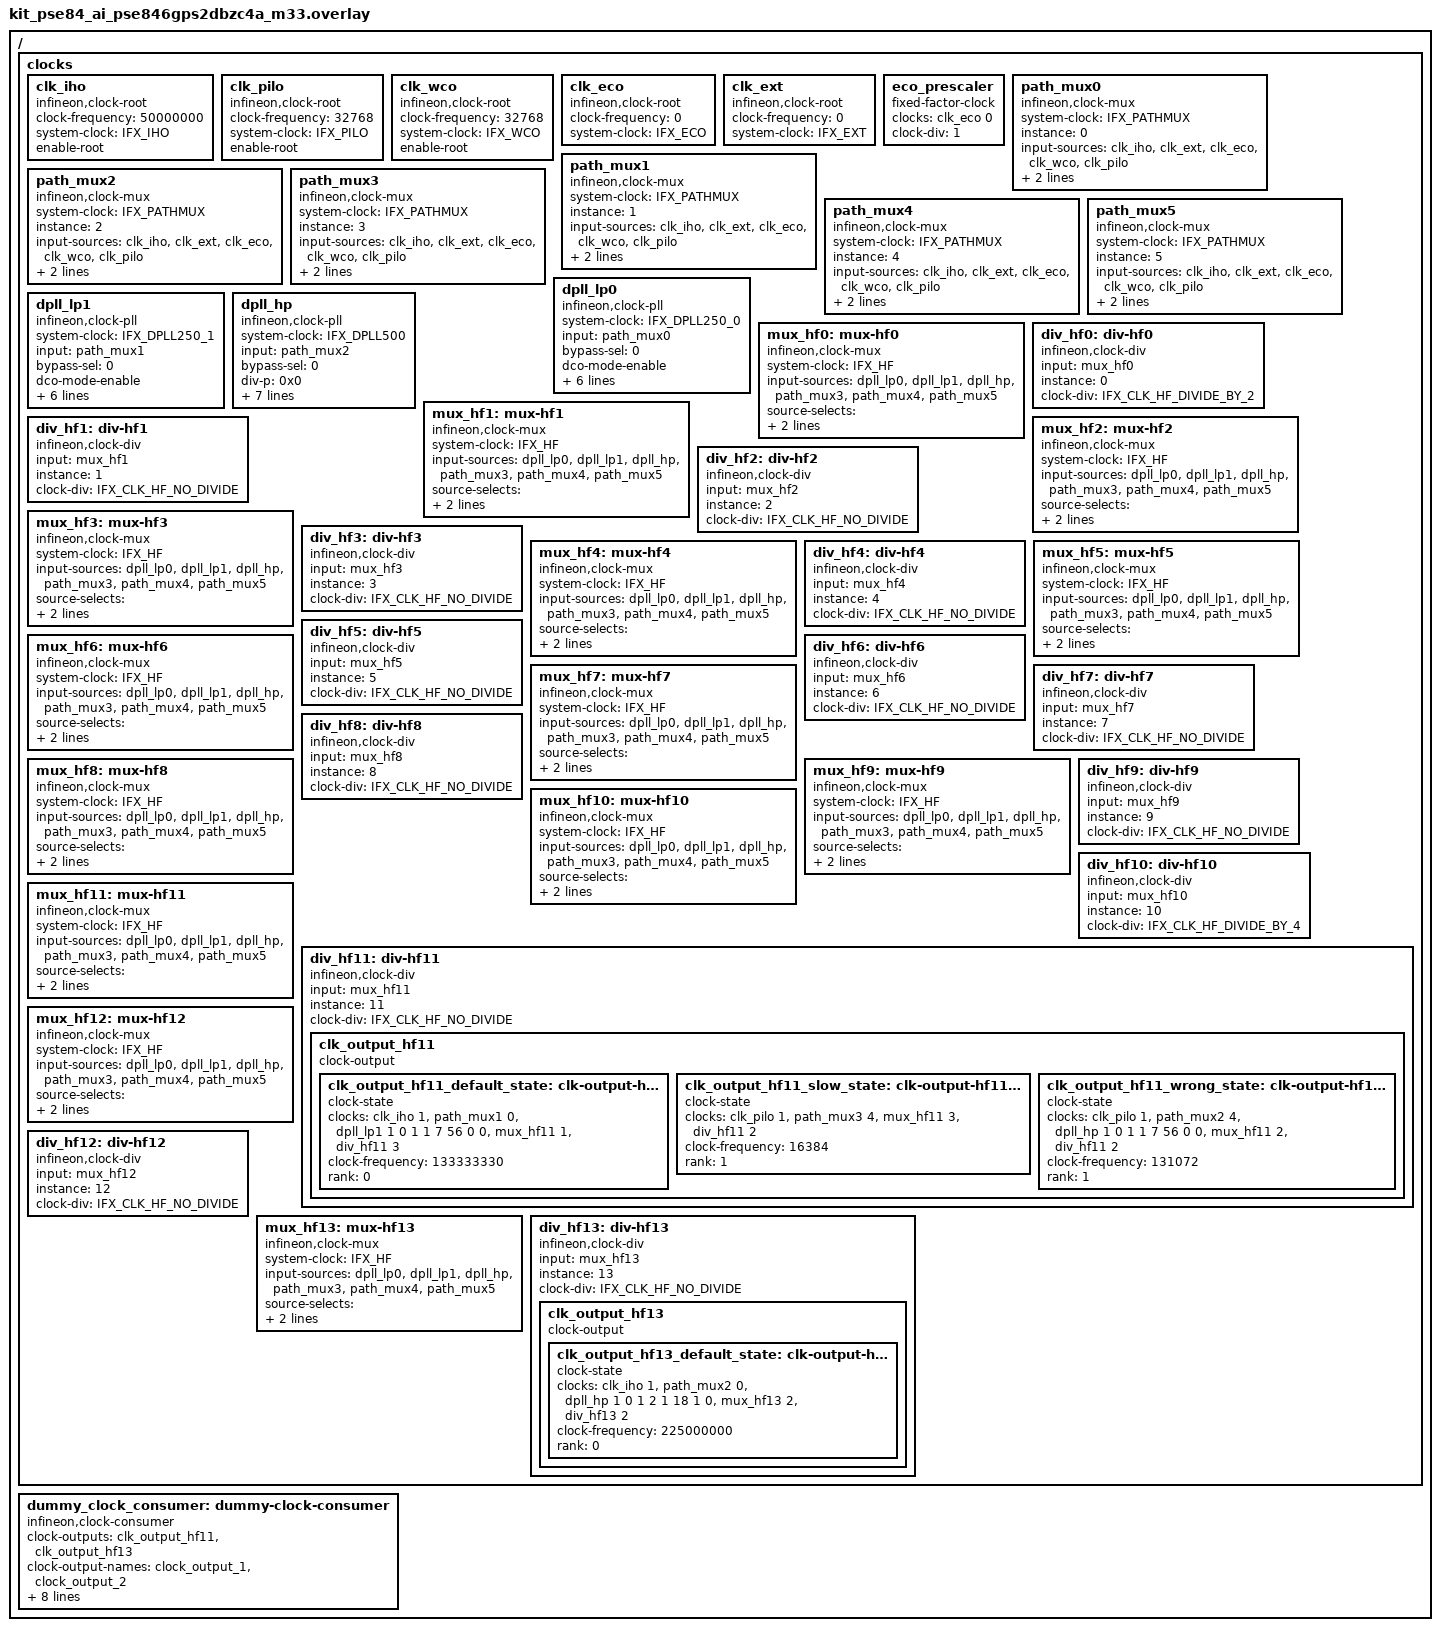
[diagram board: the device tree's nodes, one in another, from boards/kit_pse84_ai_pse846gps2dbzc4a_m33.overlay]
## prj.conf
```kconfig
CONFIG_ZTEST=y
CONFIG_BUILD_OUTPUT_HEX=y
CONFIG_CLOCK_MANAGEMENT=y
```

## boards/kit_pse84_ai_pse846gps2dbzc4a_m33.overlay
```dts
/*
 * SPDX-FileCopyrightText: Copyright (c) 2026 Infineon Technologies AG,
 * or an affiliate of Infineon Technologies AG. All rights reserved.
 *
 * SPDX-License-Identifier: Apache-2.0
 */

/*
 * PSoC Edge E84 clock tree modelled with the clock-management RFC producers.
 *
 * Clock management owns the shared upstream: every source, path multiplexer,
 * DPLL, and clk_hf root is a clock-management producer with real parent phandle
 * links (input / input-sources). The peripheral leaf dividers below stay on the
 * legacy infineon,peri-div clock-control path, owned by the peripheral drivers,
 * so drivers can move to clock management one at a time.
 *
 * Register addresses and bitfield positions on the upstream producers feed the
 * register-direct backend; the PDL backend ignores them. Addresses in the dts
 * file need  register - level driver.
 * Addresses are from the PSOC Control C3 Registers Reference Manual (SRSS chapter).
 *
 * The DPLL programming sequence is retained through the vendor library, so the
 * DPLL producers are used unchanged by both backends.
 */

#include <zephyr/dt-bindings/clock/ifx_clock_source_common.h>
#include <zephyr/dt-bindings/clock/ifx_clock_source_pse8xx.h>

/delete-node/ &clk_iho;
/delete-node/ &clk_pilo;
/delete-node/ &path_mux0;
/delete-node/ &path_mux1;
/delete-node/ &path_mux2;
/delete-node/ &path_mux3;
/delete-node/ &path_mux4;
/delete-node/ &path_mux5;
/delete-node/ &dpll_lp0;
/delete-node/ &dpll_lp1;
/delete-node/ &dpll_hp;
/delete-node/ &clk_hf0;
/delete-node/ &clk_hf1;
/delete-node/ &clk_hf2;
/delete-node/ &clk_hf3;
/delete-node/ &clk_hf4;
/delete-node/ &clk_hf5;
/delete-node/ &clk_hf6;
/delete-node/ &clk_hf7;
/delete-node/ &clk_hf8;
/delete-node/ &clk_hf9;
/delete-node/ &clk_hf10;
/delete-node/ &clk_hf11;
/delete-node/ &clk_hf12;
/delete-node/ &clk_hf13;



/ {
	/* Clock tree 1/3: roots and path muxes (the 3 /clocks blocks merge). */
	clocks {
		/*
		 * Root oscillator sources (TRM 21.3).
		 */

		/*
		 * Default clock source fixed frequency of 50MHz.
		 */
		clk_iho: clk_iho {
			compatible = "infineon,clock-root";
			#clock-cells = <1>;
			clock-frequency = <50000000>;
			system-clock = <IFX_IHO>;
			enable-root;
			status = "okay";
		};

		/*
		 * Precision-Low Power clock. 
		 */

		clk_pilo: clk_pilo {
			compatible = "infineon,clock-root";
			#clock-cells = <1>;
			clock-frequency = <32768>;
			system-clock = <IFX_PILO>;
			enable-root;
			status = "okay";
		};

		clk_wco: clk_wco {
			compatible = "infineon,clock-root";
			#clock-cells = <1>;
			clock-frequency = <32768>;
			system-clock = <IFX_WCO>;
			enable-root;
			status = "okay";
		};

		/*
		 * ECO and EXT_CLK need board components (a crystal or a driven
		 * clock pin)
		 */
		clk_eco: clk_eco {
			compatible = "infineon,clock-root";
			#clock-cells = <1>;
			clock-frequency = <0>;
			system-clock = <IFX_ECO>;
			status = "okay";
		};


		clk_ext: clk_ext {
			compatible = "infineon,clock-root";
			#clock-cells = <1>;
			clock-frequency = <0>;
			system-clock = <IFX_EXT>;
			status = "okay";
		};

		/*
		 * ECO prescaler (TRM 19.3.7); one of the CLK_LF source options.
		 * Disabled with its ECO parent: the generic fixed-factor
		 * producer would otherwise reference a clock object that a
		 * disabled clk_eco never emits.
		 */
		eco_prescaler: eco_prescaler {
			compatible = "fixed-factor-clock";
			#clock-cells = <0>;
			clocks = <&clk_eco 0>;
			clock-div = <1>;
			status = "okay";
		};

		/*
		 * Each clock path mux has a dsi mux which selects a 
		 * low frequency clock to clock a path.
		 * WCO - PILO
		 */
		/*
		 * Each clock-path has a mux that determines its source. 
		 * IHO - EXTCLK - ECO - DSI( WCO - PILO)
		 */
		path_mux0: path_mux0 {
			compatible = "infineon,clock-mux";
			#clock-cells = <1>;
			system-clock = < IFX_PATHMUX >;
			instance = <0>;
			input-sources = <&clk_iho &clk_ext &clk_eco &clk_wco &clk_pilo>;
			source-selects = < IFX_CAT1_CLKPATH_IN_IHO IFX_CAT1_CLKPATH_IN_EXT 
					   IFX_CAT1_CLKPATH_IN_ECO IFX_CAT1_CLKPATH_IN_WCO 
					   IFX_CAT1_CLKPATH_IN_PILO >;
			status = "okay";
		};

		path_mux1: path_mux1 {
			compatible = "infineon,clock-mux";
			#clock-cells = <1>;
			system-clock = < IFX_PATHMUX >;
			instance = <1>;
			input-sources = <&clk_iho &clk_ext &clk_eco &clk_wco &clk_pilo>;
			source-selects = < IFX_CAT1_CLKPATH_IN_IHO IFX_CAT1_CLKPATH_IN_EXT 
					   IFX_CAT1_CLKPATH_IN_ECO IFX_CAT1_CLKPATH_IN_WCO 
					   IFX_CAT1_CLKPATH_IN_PILO >;
			status = "okay";
		};

		path_mux2: path_mux2 {
			compatible = "infineon,clock-mux";
			#clock-cells = <1>;
			system-clock = < IFX_PATHMUX >;
			instance = <2>;
			input-sources = <&clk_iho &clk_ext &clk_eco &clk_wco &clk_pilo>;
			source-selects = < IFX_CAT1_CLKPATH_IN_IHO IFX_CAT1_CLKPATH_IN_EXT 
					   IFX_CAT1_CLKPATH_IN_ECO IFX_CAT1_CLKPATH_IN_WCO 
					   IFX_CAT1_CLKPATH_IN_PILO >;
			status = "okay";
		};

		path_mux3: path_mux3 {
			compatible = "infineon,clock-mux";
			#clock-cells = <1>;
			system-clock = < IFX_PATHMUX >;
			instance = <3>;
			input-sources = <&clk_iho &clk_ext &clk_eco &clk_wco &clk_pilo>;
			source-selects = < IFX_CAT1_CLKPATH_IN_IHO IFX_CAT1_CLKPATH_IN_EXT 
					   IFX_CAT1_CLKPATH_IN_ECO IFX_CAT1_CLKPATH_IN_WCO 
					   IFX_CAT1_CLKPATH_IN_PILO >;
			status = "okay";
		};

		path_mux4: path_mux4 {
			compatible = "infineon,clock-mux";
			#clock-cells = <1>;
			system-clock = < IFX_PATHMUX >;
			instance = <4>;
			input-sources = <&clk_iho &clk_ext &clk_eco &clk_wco &clk_pilo>;
			source-selects = < IFX_CAT1_CLKPATH_IN_IHO IFX_CAT1_CLKPATH_IN_EXT 
					   IFX_CAT1_CLKPATH_IN_ECO IFX_CAT1_CLKPATH_IN_WCO 
					   IFX_CAT1_CLKPATH_IN_PILO >;
			status = "okay";
		};

		path_mux5: path_mux5 {
			compatible = "infineon,clock-mux";
			#clock-cells = <1>;
			system-clock = < IFX_PATHMUX >;
			instance = <5>;
			input-sources = <&clk_iho &clk_ext &clk_eco &clk_wco &clk_pilo>;
			source-selects = < IFX_CAT1_CLKPATH_IN_IHO IFX_CAT1_CLKPATH_IN_EXT 
					   IFX_CAT1_CLKPATH_IN_ECO IFX_CAT1_CLKPATH_IN_WCO 
					   IFX_CAT1_CLKPATH_IN_PILO >;
			status = "okay";
		};
	};
};

/ {
	/* Clock tree 2/3: FLL, DPLLs, and the clk_hf roots. */
	clocks {
		/*
		 * The DPLL_i sits in CLK_PATH_i with path_mux_i as its reference.
		 */

		dpll_lp0: dpll_lp0 {
			compatible = "infineon,clock-pll";
			#clock-cells = < 8 >;  
			system-clock = < IFX_DPLL250_0 >;          
			input = < &path_mux0 >;
			bypass-sel = < 0 >;
			dco-mode-enable;
			output-div = < 1 >;
			reference-div = < 7 >; 
			feedback-div = < 56 >;
			fraction-enable = <0>;        
			fraction-div = < 0x0 >;            
			clock-frequency = < 400000000 >; 
			status = "okay";                            
		};

		dpll_lp1: dpll_lp1 {
			compatible = "infineon,clock-pll";
			#clock-cells = < 8 >;  
			system-clock = < IFX_DPLL250_1 >;          
			input = < &path_mux1 >;
			bypass-sel = < 0 >;
			dco-mode-enable;
			output-div = < 1 >;
			reference-div = < 7 >; 
			feedback-div = < 56 >;
			fraction-enable = <0>;       
			fraction-div = < 0x0 >;            
			clock-frequency = < 400000000 >; 
			status = "okay"; 
		};
		
		dpll_hp: dpll_hp {          
			compatible = "infineon,clock-pll";
			#clock-cells = < 8 >;
			system-clock = < IFX_DPLL500 >;
			input = < &path_mux2 >;
			bypass-sel = < 0 >;         
			div-p = < 0x0 >;                     
			div-n = < 0xb >;                    
			div-k = < 0x1 >;                     
			fraction-div = < 0x0 >;              
			freq-mode-sel = < 0x7 >;            
			flock-enable-threshold = < 0x3 >;    
			lf-beta-value = < 0x14 >;
			clock-frequency = < 0x11e1a300 >;
			status = "okay";         
		};

		/*
		 * Each high freq clock selects a clock path via ROOT_MUX
		 * and applies a predivider.
		 */


		mux_hf0: mux-hf0 {
			compatible = "infineon,clock-mux";
			#clock-cells = <1>;
			system-clock = < IFX_HF >;
			input-sources = < &dpll_lp0 &dpll_lp1 &dpll_hp &path_mux3 &path_mux4 &path_mux5 >;
			source-selects = < IFX_CLK_HF_IN_CLKPATH0 IFX_CLK_HF_IN_CLKPATH1 
					   IFX_CLK_HF_IN_CLKPATH2 IFX_CLK_HF_IN_CLKPATH3 
					   IFX_CLK_HF_IN_CLKPATH4 IFX_CLK_HF_IN_CLKPATH5 >;
			instance = <0>;
			status = "okay";
		};

		div_hf0: div-hf0 {
			compatible = "infineon,clock-div";
			#clock-cells = <1>;
			input = <&mux_hf0>;
			instance = < 0 >;
			clock-div = <IFX_CLK_HF_DIVIDE_BY_2>;
			status = "okay";
		};

		mux_hf1: mux-hf1 {
			compatible = "infineon,clock-mux";
			#clock-cells = <1>;
			system-clock = < IFX_HF >;
			input-sources = < &dpll_lp0 &dpll_lp1 &dpll_hp &path_mux3 &path_mux4 &path_mux5 >;
			source-selects = < IFX_CLK_HF_IN_CLKPATH0 IFX_CLK_HF_IN_CLKPATH1 
					   IFX_CLK_HF_IN_CLKPATH2 IFX_CLK_HF_IN_CLKPATH3 
					   IFX_CLK_HF_IN_CLKPATH4 IFX_CLK_HF_IN_CLKPATH5 >;
			instance = <1>;
			status = "okay";
		};

		div_hf1: div-hf1 {
			compatible = "infineon,clock-div";
			#clock-cells = <1>;
			input = <&mux_hf1>;
			instance = < 1 >;
			clock-div = <IFX_CLK_HF_NO_DIVIDE>;
			status = "okay";
		};

		mux_hf2: mux-hf2 {
			compatible = "infineon,clock-mux";
			#clock-cells = <1>;
			system-clock = < IFX_HF >;
			input-sources = < &dpll_lp0 &dpll_lp1 &dpll_hp &path_mux3 &path_mux4 &path_mux5 >;
			source-selects = < IFX_CLK_HF_IN_CLKPATH0 IFX_CLK_HF_IN_CLKPATH1 
					   IFX_CLK_HF_IN_CLKPATH2 IFX_CLK_HF_IN_CLKPATH3 
					   IFX_CLK_HF_IN_CLKPATH4 IFX_CLK_HF_IN_CLKPATH5 >;
			instance = <2>;
			status = "okay";
		};

		div_hf2: div-hf2 {
			compatible = "infineon,clock-div";
			#clock-cells = <1>;
			input = <&mux_hf2>;
			instance = < 2 >;
			clock-div = <IFX_CLK_HF_NO_DIVIDE>;
			status = "okay";
		};

		mux_hf3: mux-hf3 {
			compatible = "infineon,clock-mux";
			#clock-cells = <1>;
			system-clock = < IFX_HF >;
			input-sources = < &dpll_lp0 &dpll_lp1 &dpll_hp &path_mux3 &path_mux4 &path_mux5 >;
			source-selects = < IFX_CLK_HF_IN_CLKPATH0 IFX_CLK_HF_IN_CLKPATH1 
					   IFX_CLK_HF_IN_CLKPATH2 IFX_CLK_HF_IN_CLKPATH3 
					   IFX_CLK_HF_IN_CLKPATH4 IFX_CLK_HF_IN_CLKPATH5 >;
			instance = <3>;
			status = "okay";
		};

		div_hf3: div-hf3 {
			compatible = "infineon,clock-div";
			#clock-cells = <1>;
			input = <&mux_hf3>;
			instance = < 3 >;
			clock-div = <IFX_CLK_HF_NO_DIVIDE>;
			status = "okay";
		};

		mux_hf4: mux-hf4 {
			compatible = "infineon,clock-mux";
			#clock-cells = <1>;
			system-clock = < IFX_HF >;
			input-sources = < &dpll_lp0 &dpll_lp1 &dpll_hp &path_mux3 &path_mux4 &path_mux5 >;
			source-selects = < IFX_CLK_HF_IN_CLKPATH0 IFX_CLK_HF_IN_CLKPATH1 
					   IFX_CLK_HF_IN_CLKPATH2 IFX_CLK_HF_IN_CLKPATH3 
					   IFX_CLK_HF_IN_CLKPATH4 IFX_CLK_HF_IN_CLKPATH5 >;
			instance = <4>;
			status = "okay";
		};

		div_hf4: div-hf4 {
			compatible = "infineon,clock-div";
			#clock-cells = <1>;
			input = <&mux_hf4>;
			instance = < 4 >;
			clock-div = <IFX_CLK_HF_NO_DIVIDE>;
			status = "okay";
		};

		mux_hf5: mux-hf5 {
			compatible = "infineon,clock-mux";
			#clock-cells = <1>;
			system-clock = < IFX_HF >;
			input-sources = < &dpll_lp0 &dpll_lp1 &dpll_hp &path_mux3 &path_mux4 &path_mux5 >;
			source-selects = < IFX_CLK_HF_IN_CLKPATH0 IFX_CLK_HF_IN_CLKPATH1 
					   IFX_CLK_HF_IN_CLKPATH2 IFX_CLK_HF_IN_CLKPATH3 
					   IFX_CLK_HF_IN_CLKPATH4 IFX_CLK_HF_IN_CLKPATH5 >;
			instance = <5>;
			status = "okay";
		};

		div_hf5: div-hf5 {
			compatible = "infineon,clock-div";
			#clock-cells = <1>;
			input = <&mux_hf5>;
			instance = < 5 >;
			clock-div = <IFX_CLK_HF_NO_DIVIDE>;
			status = "okay";
		};

		mux_hf6: mux-hf6 {
			compatible = "infineon,clock-mux";
			#clock-cells = <1>;
			system-clock = < IFX_HF >;
			input-sources = < &dpll_lp0 &dpll_lp1 &dpll_hp &path_mux3 &path_mux4 &path_mux5 >;
			source-selects = < IFX_CLK_HF_IN_CLKPATH0 IFX_CLK_HF_IN_CLKPATH1 
					   IFX_CLK_HF_IN_CLKPATH2 IFX_CLK_HF_IN_CLKPATH3 
					   IFX_CLK_HF_IN_CLKPATH4 IFX_CLK_HF_IN_CLKPATH5 >;
			instance = <6>;
			status = "okay";
		};

		div_hf6: div-hf6 {
			compatible = "infineon,clock-div";
			#clock-cells = <1>;
			input = <&mux_hf6>;
			instance = < 6 >;
			clock-div = <IFX_CLK_HF_NO_DIVIDE>;
			status = "okay";
		};

		mux_hf7: mux-hf7 {
			compatible = "infineon,clock-mux";
			#clock-cells = <1>;
			system-clock = < IFX_HF >;
			input-sources = < &dpll_lp0 &dpll_lp1 &dpll_hp &path_mux3 &path_mux4 &path_mux5 >;
			source-selects = < IFX_CLK_HF_IN_CLKPATH0 IFX_CLK_HF_IN_CLKPATH1 
					   IFX_CLK_HF_IN_CLKPATH2 IFX_CLK_HF_IN_CLKPATH3 
					   IFX_CLK_HF_IN_CLKPATH4 IFX_CLK_HF_IN_CLKPATH5 >;
			instance = <7>;
			status = "okay";
		};

		div_hf7: div-hf7 {
			compatible = "infineon,clock-div";
			#clock-cells = <1>;
			input = <&mux_hf7>;
			instance = < 7 >;
			clock-div = <IFX_CLK_HF_NO_DIVIDE>;
			status = "okay";
		};

		mux_hf8: mux-hf8 {
			compatible = "infineon,clock-mux";
			#clock-cells = <1>;
			system-clock = < IFX_HF >;
			input-sources = < &dpll_lp0 &dpll_lp1 &dpll_hp &path_mux3 &path_mux4 &path_mux5 >;
			source-selects = < IFX_CLK_HF_IN_CLKPATH0 IFX_CLK_HF_IN_CLKPATH1 
					   IFX_CLK_HF_IN_CLKPATH2 IFX_CLK_HF_IN_CLKPATH3 
					   IFX_CLK_HF_IN_CLKPATH4 IFX_CLK_HF_IN_CLKPATH5 >;
			instance = <8>;
			status = "okay";
		};

		div_hf8: div-hf8 {
			compatible = "infineon,clock-div";
			#clock-cells = <1>;
			input = <&mux_hf8>;
			instance = < 8 >;
			clock-div = <IFX_CLK_HF_NO_DIVIDE>;
			status = "okay";
		};

		mux_hf9: mux-hf9 {
			compatible = "infineon,clock-mux";
			#clock-cells = <1>;
			system-clock = < IFX_HF >;
			input-sources = < &dpll_lp0 &dpll_lp1 &dpll_hp &path_mux3 &path_mux4 &path_mux5 >;
			source-selects = < IFX_CLK_HF_IN_CLKPATH0 IFX_CLK_HF_IN_CLKPATH1 
					   IFX_CLK_HF_IN_CLKPATH2 IFX_CLK_HF_IN_CLKPATH3 
					   IFX_CLK_HF_IN_CLKPATH4 IFX_CLK_HF_IN_CLKPATH5 >;
			instance = <9>;
			status = "okay";
		};

		div_hf9: div-hf9 {
			compatible = "infineon,clock-div";
			#clock-cells = <1>;
			input = <&mux_hf9>;
			instance = < 9 >;
			clock-div = <IFX_CLK_HF_NO_DIVIDE>;
			status = "okay";
		};

		mux_hf10: mux-hf10 {
			compatible = "infineon,clock-mux";
			#clock-cells = <1>;
			system-clock = < IFX_HF >;
			input-sources = < &dpll_lp0 &dpll_lp1 &dpll_hp &path_mux3 &path_mux4 &path_mux5 >;
			source-selects = < IFX_CLK_HF_IN_CLKPATH0 IFX_CLK_HF_IN_CLKPATH1 
					   IFX_CLK_HF_IN_CLKPATH2 IFX_CLK_HF_IN_CLKPATH3 
					   IFX_CLK_HF_IN_CLKPATH4 IFX_CLK_HF_IN_CLKPATH5 >;
			instance = <10>;
			status = "okay";
		};

		div_hf10: div-hf10 {
			compatible = "infineon,clock-div";
			#clock-cells = <1>;
			input = <&mux_hf10>;
			instance = < 10 >;
			clock-div = <IFX_CLK_HF_DIVIDE_BY_4>;
			status = "okay";
		};

		mux_hf11: mux-hf11 {
			compatible = "infineon,clock-mux";
			#clock-cells = <1>;
			system-clock = < IFX_HF >;
			input-sources = < &dpll_lp0 &dpll_lp1 &dpll_hp &path_mux3 &path_mux4 &path_mux5 >;
			source-selects = < IFX_CLK_HF_IN_CLKPATH0 IFX_CLK_HF_IN_CLKPATH1 
					   IFX_CLK_HF_IN_CLKPATH2 IFX_CLK_HF_IN_CLKPATH3 
					   IFX_CLK_HF_IN_CLKPATH4 IFX_CLK_HF_IN_CLKPATH5 >;
			instance = <11>;
			status = "okay";
		};

		div_hf11: div-hf11 {
			compatible = "infineon,clock-div";
			#clock-cells = <1>;
			input = <&mux_hf11>;
			instance = < 11 >;
			clock-div = <IFX_CLK_HF_NO_DIVIDE>;
			status = "okay";
		};

		mux_hf12: mux-hf12 {
			compatible = "infineon,clock-mux";
			#clock-cells = <1>;
			system-clock = < IFX_HF >;
			input-sources = < &dpll_lp0 &dpll_lp1 &dpll_hp &path_mux3 &path_mux4 &path_mux5 >;
			source-selects = < IFX_CLK_HF_IN_CLKPATH0 IFX_CLK_HF_IN_CLKPATH1 
					   IFX_CLK_HF_IN_CLKPATH2 IFX_CLK_HF_IN_CLKPATH3 
					   IFX_CLK_HF_IN_CLKPATH4 IFX_CLK_HF_IN_CLKPATH5 >;
			instance = <12>;
			status = "okay";
		};

		div_hf12: div-hf12 {
			compatible = "infineon,clock-div";
			#clock-cells = <1>;
			input = <&mux_hf12>;
			instance = < 12 >;
			clock-div = <IFX_CLK_HF_NO_DIVIDE>;
			status = "okay";
		};

		mux_hf13: mux-hf13 {
			compatible = "infineon,clock-mux";
			#clock-cells = <1>;
			system-clock = < IFX_HF >;
			input-sources = < &dpll_lp0 &dpll_lp1 &dpll_hp &path_mux3 &path_mux4 &path_mux5 >;
			source-selects = < IFX_CLK_HF_IN_CLKPATH0 IFX_CLK_HF_IN_CLKPATH1 
					   IFX_CLK_HF_IN_CLKPATH2 IFX_CLK_HF_IN_CLKPATH3 
					   IFX_CLK_HF_IN_CLKPATH4 IFX_CLK_HF_IN_CLKPATH5 >;
			instance = <13>;
			status = "okay";
		};

		div_hf13: div-hf13 {
			compatible = "infineon,clock-div";
			#clock-cells = <1>;
			input = <&mux_hf13>;
			instance = < 13 >;
			clock-div = <IFX_CLK_HF_NO_DIVIDE>;
			status = "okay";
		};

	};
};

/{
	dummy_clock_consumer: dummy-clock-consumer{
		compatible = "infineon,clock-consumer";
		clock-outputs = <&clk_output_hf11 &clk_output_hf13>;
		clock-output-names = "clock_output_1", "clock_output_2";
		clock-request-0 = <&clk_output_hf11_default_state &clk_output_hf13_default_state>;
		clock-request-1 = <&clk_output_hf11_slow_state &clk_output_hf13_default_state>;
		clock-request-2 = <&clk_output_hf11_wrong_state &clk_output_hf13_default_state>;
		clock-request-names = "default", "slow", "wrong";
	};
};

&div_hf11 {
	clk_output_hf11: clk_output_hf11 {
		#clock-cells = <0>;
		compatible = "clock-output";
		clk_output_hf11_default_state: clk-output-hf11-default-state {
			compatible = "clock-state";
			clocks = <&clk_iho 1>, <&path_mux1 0>, <&dpll_lp1 1 0 1 1 7 56 0 0>, <&mux_hf11 1 >, <&div_hf11 3>;
			clock-frequency = <133333330>;
			rank = < 0 >;
		};
		clk_output_hf11_slow_state: clk-output-hf11-slow-state {
			compatible = "clock-state";
			clocks = <&clk_pilo 1>, <&path_mux3 4>, <&mux_hf11 3>, <&div_hf11 2>;
			clock-frequency = <16384>;
			rank = < 1 >;
		};
		clk_output_hf11_wrong_state: clk-output-hf11-wrong-state {
			compatible = "clock-state";
			clocks = <&clk_pilo 1>, <&path_mux2 4>, <&dpll_hp 1 0 1 1 7 56 0 0>, <&mux_hf11 2>, <&div_hf11 2>;
			clock-frequency = <131072>;
			rank = < 1 >;
		};
	};
};

&div_hf13 {
	clk_output_hf13: clk_output_hf13 {
		#clock-cells = <0>;
		compatible = "clock-output";
		clk_output_hf13_default_state: clk-output-hf13-default-state {
			compatible = "clock-state";
			clocks = <&clk_iho 1>, <&path_mux2 0>, <&dpll_hp 1 0 1 2 1 18 1 0>, <&mux_hf13 2 >, <&div_hf13 2>;
			clock-frequency = <225000000>;
			rank = < 0 >;
		};
	};
};
```

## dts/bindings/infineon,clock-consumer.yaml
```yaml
compatible: "infineon,clock-consumer"

include: [clock-device.yaml, base.yaml]
```

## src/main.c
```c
#include <zephyr/ztest.h>
#include <zephyr/drivers/clock_management.h>
#include <zephyr/sys/sys_io.h>
#include <cy_sysclk.h>

#define DUMMY_CONSUMER DT_NODELABEL(dummy_clock_consumer)

struct ifx_clock_consumer_config {
	const struct clock_management_data *clk_mgmt;
};

static const struct device *dummy_device = DEVICE_DT_GET(DUMMY_CONSUMER);
static const clock_request_t default_req = CLOCK_MANAGEMENT_DT_GET_REQUEST(DUMMY_CONSUMER, default);
static const clock_request_t slow_req = CLOCK_MANAGEMENT_DT_GET_REQUEST(DUMMY_CONSUMER, slow);
static const clock_request_t wrong_req = CLOCK_MANAGEMENT_DT_GET_REQUEST(DUMMY_CONSUMER, wrong);
static const clock_output_t dummy_clk_1 = CLOCK_MANAGEMENT_DT_GET_OUTPUT_BY_NAME(DUMMY_CONSUMER, clock_output_1);
static const clock_output_t dummy_clk_2 = CLOCK_MANAGEMENT_DT_GET_OUTPUT_BY_NAME(DUMMY_CONSUMER, clock_output_2);
static const uint32_t output_1_default_freq = DT_PROP(DT_NODELABEL(clk_output_hf11_default_state),clock_frequency);
static const uint32_t output_1_slow_freq = DT_PROP(DT_NODELABEL(clk_output_hf11_slow_state),clock_frequency); 
static const uint32_t output_2_default_freq = DT_PROP(DT_NODELABEL(clk_output_hf13_default_state),clock_frequency); 

void reset_clock_states(void *unused)
{
	ARG_UNUSED(unused);
	const struct ifx_clock_consumer_config *config = dummy_device->config;
	int ret;
	ret = clock_management_request_state(config->clk_mgmt,default_req);
	zassert_equal(ret, 0, "Failed to apply reset state, ret=%d", ret);
}

/*
Test case. Verifies a specific and well defined functionality;
by default all test cases shall be start with test_
*/

ZTEST(dummy_minimal_tests, test_clock_output_1)
{
	int ret;
	const struct ifx_clock_consumer_config *config = dummy_device->config;
	ret = clock_management_request_state(config->clk_mgmt,default_req);
	zassert_equal(ret, 0, "Failed to apply default state, ret_value=%08x", ret);
	ret = clock_management_get_rate(config->clk_mgmt,dummy_clk_1);
	zassert_equal((uint32_t)ret, output_1_default_freq, "Invalid clock default, ret_value=%d", ret);
	ret = clock_management_on(config->clk_mgmt,dummy_clk_1);
	zassert_equal(ret, 0, "Invalid clock default, ret_value=%d", ret);
	ret = clock_management_off(config->clk_mgmt,dummy_clk_1);
	zassert_equal(ret, 0, "Invalid clock default, ret_value=%d", ret);
	ret = clock_management_on(config->clk_mgmt,dummy_clk_1);
	zassert_equal(ret, 0, "Invalid clock default, ret_value=%d", ret);
	ret = clock_management_get_rate(config->clk_mgmt,dummy_clk_1);
	zassert_equal((uint32_t)ret, output_1_default_freq, "Invalid clock default, ret_value=%d", ret);
	ret = clock_management_off(config->clk_mgmt,dummy_clk_1);
	zassert_equal(ret, 0, "Invalid clock default, ret_value=%d", ret);
	ret = clock_management_get_rate(config->clk_mgmt,dummy_clk_1);
	zassert_equal((uint32_t)ret, output_1_default_freq, "Invalid clock default, ret_value=%d", ret);
}

ZTEST(dummy_minimal_tests, test_slow_state)
{
	const struct ifx_clock_consumer_config *config = dummy_device->config;
	int ret;
	ret = clock_management_request_state(config->clk_mgmt,slow_req);
	zassert_equal(ret, 0, "Faile to apply slow state, ret_value=%08x", ret);
	ret = clock_management_get_rate(config->clk_mgmt,dummy_clk_1);
	zassert_equal((uint32_t)ret, output_1_slow_freq, "Rates dont match, ret_value=%d", ret);
	ret = clock_management_get_rate(config->clk_mgmt,dummy_clk_2);
	zassert_equal((uint32_t)ret, output_2_default_freq, "Rates dont match, ret_value=%d", ret);
	ret = clock_management_off(config->clk_mgmt,dummy_clk_2);
	zassert_equal(ret, 0, "Invalid clock default, ret_value=%d", ret);
	ret = clock_management_get_rate(config->clk_mgmt,dummy_clk_2);
	zassert_equal((uint32_t)ret, output_2_default_freq, "Invalid clock default, ret_value=%d", ret);
	ret = clock_management_on(config->clk_mgmt,dummy_clk_2);
	zassert_equal(ret, 0, "Invalid clock default, ret_value=%d", ret);
	ret = clock_management_get_rate(config->clk_mgmt,dummy_clk_1);
	zassert_equal((uint32_t)ret, output_1_slow_freq, "Invalid clock default, ret_value=%d", ret);
	ret = clock_management_off(config->clk_mgmt,dummy_clk_1);
	zassert_equal(ret, 0, "Invalid clock default, ret_value=%d", ret);
	ret = clock_management_get_rate(config->clk_mgmt,dummy_clk_1);
	zassert_equal((uint32_t)ret, output_1_slow_freq, "Invalid clock default, ret_value=%d", ret);
}


ZTEST(dummy_minimal_tests, test_wrong_state)
{
	const struct ifx_clock_consumer_config *config = dummy_device->config;
	int ret;
	ret = clock_management_request_state(config->clk_mgmt,wrong_req);
	zassert_not_equal(ret, 0, "Wrong state applied, ret_value=%08x", ret);
	/*PLL does not lock - Very low input freq*/
}



/*
 * Sequential order: Full clock_output_1 test followed by full clock_output_2 test.
                     Starts with clock path off.
 */




ZTEST_SUITE(dummy_minimal_tests, NULL, NULL, reset_clock_states, NULL, NULL);
```
